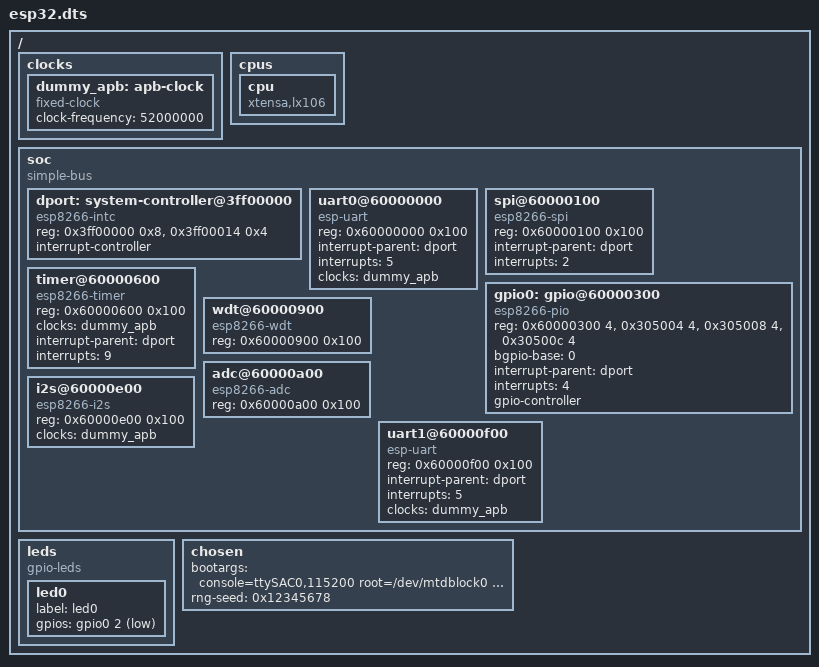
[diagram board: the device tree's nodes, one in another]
/dts-v1/;
#include <dt-bindings/gpio/gpio.h>
#include <dt-bindings/input/input.h>

/ {
    #address-cells = <1>;
    #size-cells = <1>;
    
    clocks {
        dummy_apb: apb-clock {
            #clock-cells = <0>;
            compatible = "fixed-clock";
            clock-frequency = <52000000>;
        };
    };
    
    cpus{
        cpu {
            compatible = "xtensa,lx106";
            device_type = "cpu";
        };
    };

    soc {
        #address-cells = <1>;
        #size-cells = <1>;
        compatible = "simple-bus";
        ranges;
        
        dport: system-controller@3ff00000 {
            #interrupt-cells = <1>;
            #address-cells = <0>;
            #clock-cells = <0>;
            compatible = "esp8266-intc";
            reg-names = "intc", "ccu";
            reg = <0x3ff00000 0x8>, <0x3ff00014 0x4>;
            interrupt-controller;
        };
        
        uart0@60000000 {
            compatible = "esp-uart";
            reg = <0x60000000 0x100>;
            interrupt-parent = <&dport>;
            interrupts = <5>;
            clocks = <&dummy_apb>;
        };
        
        spi@60000100 {
            compatible = "esp8266-spi";
            reg = <0x60000100 0x100>;
            interrupt-parent = <&dport>;
            interrupts = <2>;
        };        

        gpio0: gpio@60000300 {
            #gpio-cells = <2>;
            compatible = "esp8266-pio";
            reg-names = "dirout", "dat", "set", "clr";
            reg = <0x60000300 4>, <0x305004 4>, <0x305008 4>, <0x30500c 4>;
            bgpio-base = <0>;
            interrupt-parent = <&dport>;
            interrupts = <4>;
            gpio-controller;
        };

        timer@60000600 {
            compatible = "esp8266-timer";
            reg = <0x60000600 0x100>;
            clocks = <&dummy_apb>;
            interrupt-parent = <&dport>;
            interrupts = <9>;
        };
            
        wdt@60000900 {
            compatible = "esp8266-wdt";
            reg = <0x60000900 0x100>;
        }; 
        
        adc@60000a00 {
            compatible = "esp8266-adc";
            reg = <0x60000a00 0x100>;
        };           
        
        i2s@60000e00 {
            compatible = "esp8266-i2s";
            reg = <0x60000e00 0x100>;
            clocks = <&dummy_apb>;
        };
        
        uart1@60000f00 {
            compatible = "esp-uart";
            reg = <0x60000f00 0x100>;
            interrupt-parent = <&dport>;
            interrupts = <5>;
            clocks = <&dummy_apb>;
        };        
    };
    
    leds{
        compatible = "gpio-leds";
        led0 {
            label = "led0";
            gpios = <&gpio0 2 GPIO_ACTIVE_LOW>;
        };
    };

    chosen {
        bootargs = "console=ttySAC0,115200 root=/dev/mtdblock0 rw";
        rng-seed = <0x12345678>;
    };
};
